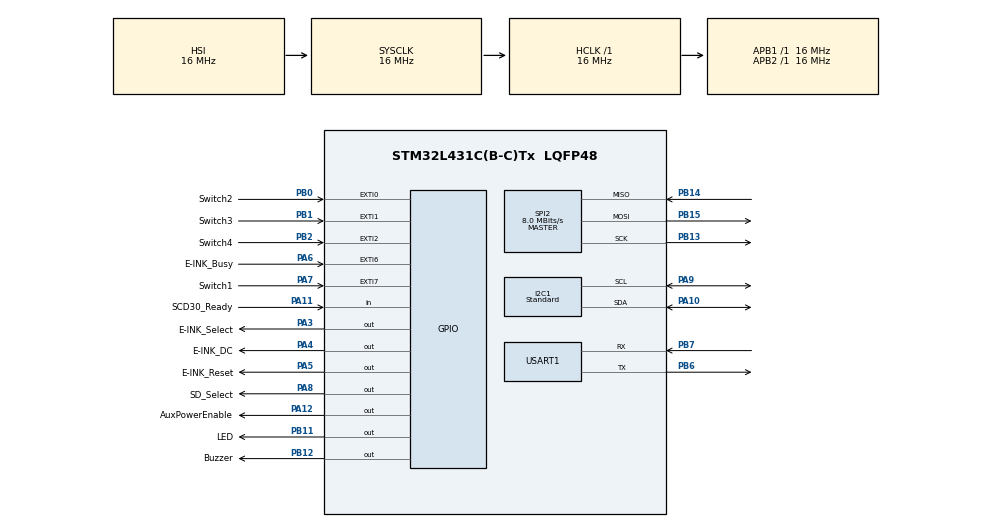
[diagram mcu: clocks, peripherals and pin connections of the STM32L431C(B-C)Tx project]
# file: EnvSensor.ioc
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ADC1.Channel-0\#ChannelRegularConversion=ADC_CHANNEL_VREFINT
ADC1.ClockPrescaler=ADC_CLOCK_ASYNC_DIV64
ADC1.NbrOfConversionFlag=1
ADC1.OffsetNumber-0\#ChannelRegularConversion=ADC_OFFSET_NONE
ADC1.Rank-0\#ChannelRegularConversion=1
ADC1.Resolution=ADC_RESOLUTION_10B
ADC1.SamplingTime-0\#ChannelRegularConversion=ADC_SAMPLETIME_2CYCLES_5
ADC1.master=1
CRC.DefaultInitValueUse=DEFAULT_INIT_VALUE_ENABLE
CRC.DefaultPolynomialUse=DEFAULT_POLYNOMIAL_ENABLE
FATFS._FS_LOCK=2
FATFS._MAX_SS=1024
FATFS._USE_LFN=1
I2C1.I2C_Speed_Mode=I2C_Standard
I2C1.NoStretchMode=I2C_NOSTRETCH_DISABLE
I2C1.Timing=0x00303D5B
Mcu.Family=STM32L4
Mcu.Name=STM32L431C(B-C)Tx
Mcu.Package=LQFP48
Mcu.UserConstants=READOUT_RETRY_INTERVAL,0.5;DISPLAY_REFRESH_INTERVAL,5 * 60;MEASUREMENT_INTERVAL,60
NVIC.EXTI0_IRQn=true\:0\:0\:false\:false\:true\:true\:true
NVIC.EXTI1_IRQn=true\:0\:0\:false\:false\:true\:true\:true
NVIC.EXTI2_IRQn=true\:0\:0\:false\:false\:true\:true\:true
NVIC.EXTI9_5_IRQn=true\:0\:0\:false\:false\:true\:true\:true
NVIC.PriorityGroup=NVIC_PRIORITYGROUP_4
NVIC.RTC_WKUP_IRQn=true\:0\:0\:false\:false\:true\:true\:true
NVIC.TIM1_BRK_TIM15_IRQn=true\:0\:0\:false\:false\:true\:true\:true
NVIC.TIM2_IRQn=true\:0\:0\:false\:false\:true\:true\:true
PA10.Mode=I2C
PA10.Signal=I2C1_SDA
PA11.GPIO_Label=SCD30_Ready
PA11.Signal=GPIO_Input
PA12.GPIO_Label=AuxPowerEnable
PA12.Signal=GPIO_Output
PA13\ (JTMS-SWDIO).Mode=Trace_Asynchronous_SW
PA13\ (JTMS-SWDIO).Signal=SYS_JTMS-SWDIO
PA14\ (JTCK-SWCLK).Mode=Trace_Asynchronous_SW
PA14\ (JTCK-SWCLK).Signal=SYS_JTCK-SWCLK
PA3.GPIO_Label=E-INK_Select
PA3.PinState=GPIO_PIN_SET
PA3.Signal=GPIO_Output
PA4.GPIO_Label=E-INK_DC
PA4.Signal=GPIO_Output
PA5.GPIO_Label=E-INK_Reset
PA5.PinState=GPIO_PIN_RESET
PA5.Signal=GPIO_Output
PA6.GPIO_Label=E-INK_Busy
PA6.Signal=GPXTI6
PA7.GPIO_Label=Switch1
PA7.GPIO_ModeDefaultEXTI=GPIO_MODE_IT_FALLING
PA7.Signal=GPXTI7
PA8.GPIO_Label=SD_Select
PA8.PinState=GPIO_PIN_SET
PA8.Signal=GPIO_Output
PA9.Mode=I2C
PA9.Signal=I2C1_SCL
PB0.GPIO_Label=Switch2
PB0.GPIO_ModeDefaultEXTI=GPIO_MODE_IT_FALLING
PB0.Signal=GPXTI0
PB1.GPIO_Label=Switch3
PB1.GPIO_ModeDefaultEXTI=GPIO_MODE_IT_FALLING
PB1.Signal=GPXTI1
PB11.GPIO_Label=LED
PB11.Signal=GPIO_Output
PB12.GPIO_Label=Buzzer
PB12.Signal=GPIO_Output
PB13.Mode=Full_Duplex_Master
PB13.Signal=SPI2_SCK
PB14.Mode=Full_Duplex_Master
PB14.Signal=SPI2_MISO
PB15.Mode=Full_Duplex_Master
PB15.Signal=SPI2_MOSI
PB2.GPIO_Label=Switch4
PB2.GPIO_ModeDefaultEXTI=GPIO_MODE_IT_FALLING
PB2.Signal=GPXTI2
PB3\ (JTDO-TRACESWO).Mode=Trace_Asynchronous_SW
PB3\ (JTDO-TRACESWO).Signal=SYS_JTDO-SWO
PB6.Mode=Asynchronous
PB6.Signal=USART1_TX
PB7.Mode=Asynchronous
PB7.Signal=USART1_RX
PC14-OSC32_IN\ (PC14).Mode=LSE-External-Oscillator
PC14-OSC32_IN\ (PC14).Signal=RCC_OSC32_IN
PC15-OSC32_OUT\ (PC15).Mode=LSE-External-Oscillator
PC15-OSC32_OUT\ (PC15).Signal=RCC_OSC32_OUT
ProjectManager.HeapSize=0x100
ProjectManager.StackSize=0x400
ProjectManager.TargetToolchain=STM32CubeIDE
RCC.ADCFreq_Value=32000000
RCC.AHBFreq_Value=16000000
RCC.APB1Freq_Value=16000000
RCC.APB1TimFreq_Value=16000000
RCC.APB2Freq_Value=16000000
RCC.APB2TimFreq_Value=16000000
RCC.CortexFreq_Value=16000000
RCC.HCLKFreq_Value=16000000
RCC.HSE_VALUE=8000000
RCC.HSI48_VALUE=48000000
RCC.HSI_VALUE=16000000
RCC.MSI_VALUE=4000000
RCC.PLLSAI1N=16
RCC.RTCClockSelection=RCC_RTCCLKSOURCE_LSE
RCC.SYSCLKFreq_VALUE=16000000
RCC.SYSCLKSource=RCC_SYSCLKSOURCE_HSI
RCC.VCOOutputFreq_Value=32000000
RTC.AsynchPrediv=127
RTC.Date=1
RTC.Format=RTC_FORMAT_BIN
RTC.Month=RTC_MONTH_JANUARY
RTC.WakeUpClock-WakeUp=RTC_WAKEUPCLOCK_CK_SPRE_16BITS
RTC.WakeUpCounter-WakeUp=DISPLAY_REFRESH_INTERVAL - 1
RTC.Year=21
SPI2.BaudRatePrescaler=SPI_BAUDRATEPRESCALER_2
SPI2.CalculateBaudRate=8.0 MBits/s
SPI2.DataSize=SPI_DATASIZE_8BIT
SPI2.Direction=SPI_DIRECTION_2LINES
SPI2.Mode=SPI_MODE_MASTER
SPI2.NSSPMode=SPI_NSS_PULSE_ENABLE
SPI2.VirtualType=VM_MASTER
STMicroelectronics.X-CUBE-TOUCHGFX.4.15.0.ApplicationCcGraphicsJjApplication=TouchGFXOoGenerator
STMicroelectronics.X-CUBE-TOUCHGFX.4.15.0.tgfx_buffering_strategy=Single
STMicroelectronics.X-CUBE-TOUCHGFX.4.15.0.tgfx_custom_height=300
STMicroelectronics.X-CUBE-TOUCHGFX.4.15.0.tgfx_custom_width=400
STMicroelectronics.X-CUBE-TOUCHGFX.4.15.0.tgfx_pixel_format=Grey2\:2
TIM15.Period=15624 * 4 * READOUT_RETRY_INTERVAL
TIM15.Prescaler=255
TIM2.ClockDivision=TIM_CLOCKDIVISION_DIV1
TIM2.Period=15625 * 4 * MEASUREMENT_INTERVAL - 1
TIM2.Prescaler=255
USART1.VirtualMode-Asynchronous=VM_ASYNC
VP_ADC1_Vref_Input.Mode=IN-Vrefint
VP_CRC_VS_CRC.Mode=CRC_Activate
VP_FATFS_VS_Generic.Mode=User_defined
VP_RTC_VS_RTC_Activate.Mode=RTC_Enabled
VP_RTC_VS_RTC_Calendar.Mode=RTC_Calendar
VP_RTC_VS_RTC_WakeUp_intern.Mode=WakeUp
VP_STMicroelectronics.X-CUBE-TOUCHGFX_VS_GraphicsJjApplication_4.15.0.Mode=GraphicsJjApplication
VP_TIM15_VS_ClockSourceINT.Mode=Internal
VP_TIM2_VS_ClockSourceINT.Mode=Internal
board=custom

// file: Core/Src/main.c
/* USER CODE BEGIN Header */
/**
  ******************************************************************************
  * @file           : main.c
  * @brief          : Main program body
  ******************************************************************************
  * @attention
  *
  * <h2><center>&copy; Copyright (c) 2020 STMicroelectronics.
  * All rights reserved.</center></h2>
  *
  * This software component is licensed by ST under BSD 3-Clause license,
  * the "License"; You may not use this file except in compliance with the
  * License. You may obtain a copy of the License at:
  *                        opensource.org/licenses/BSD-3-Clause
  *
  ******************************************************************************
  */
/* USER CODE END Header */
#include "main.h"
#include "fatfs.h"
#include "app_touchgfx.h"

/* USER CODE BEGIN Includes */

#include "EnvSensor.hpp"

/* USER CODE END Includes */

ADC_HandleTypeDef hadc1;

CRC_HandleTypeDef hcrc;

I2C_HandleTypeDef hi2c1;

RTC_HandleTypeDef hrtc;

SPI_HandleTypeDef hspi2;

TIM_HandleTypeDef htim2;
TIM_HandleTypeDef htim15;

UART_HandleTypeDef huart1;

void SystemClock_Config(void);
static void MX_GPIO_Init(void);
static void MX_I2C1_Init(void);
static void MX_SPI2_Init(void);
static void MX_USART1_UART_Init(void);
static void MX_CRC_Init(void);
static void MX_TIM2_Init(void);
static void MX_TIM15_Init(void);
static void MX_RTC_Init(void);
static void MX_ADC1_Init(void);

int main(void)
{

  /* MCU Configuration--------------------------------------------------------*/

  /* Reset of all peripherals, Initializes the Flash interface and the Systick. */
  HAL_Init();

  /* Configure the system clock */
  SystemClock_Config();

  /* Initialize all configured peripherals */
  MX_GPIO_Init();
  MX_I2C1_Init();
  MX_SPI2_Init();
  MX_USART1_UART_Init();
  MX_CRC_Init();
  MX_TIM2_Init();
  MX_TIM15_Init();
  MX_RTC_Init();
  MX_ADC1_Init();
  MX_FATFS_Init();
  MX_TouchGFX_Init();
  /* USER CODE BEGIN 2 */

  // prevent Tim15 from firing interrupt right after starting it
  __HAL_TIM_CLEAR_FLAG(&htim15, TIM_SR_UIF);

  EnvSensor_Init();

  // make initial draw
  MX_TouchGFX_Process();
uint32_t duration;
  /* USER CODE END 2 */

  /* Infinite loop */
  /* USER CODE BEGIN WHILE */
  while (1)
  {
	  EnvSensor_Loop();
	  uint32_t start = HAL_GetTick();
    /* USER CODE END WHILE */

  MX_TouchGFX_Process();
    /* USER CODE BEGIN 3 */
  	  duration = HAL_GetTick() - start;
  	  if (duration > 0) {
  		  duration++;
  	  }
  }
  /* USER CODE END 3 */
}

void SystemClock_Config(void)
{
  RCC_OscInitTypeDef RCC_OscInitStruct = {0};
  RCC_ClkInitTypeDef RCC_ClkInitStruct = {0};
  RCC_PeriphCLKInitTypeDef PeriphClkInit = {0};

  /** Configure LSE Drive Capability
  */
  HAL_PWR_EnableBkUpAccess();
  __HAL_RCC_LSEDRIVE_CONFIG(RCC_LSEDRIVE_LOW);
  /** Initializes the RCC Oscillators according to the specified parameters
  * in the RCC_OscInitTypeDef structure.
  */
  RCC_OscInitStruct.OscillatorType = RCC_OSCILLATORTYPE_HSI|RCC_OSCILLATORTYPE_LSE
                              |RCC_OSCILLATORTYPE_MSI;
  RCC_OscInitStruct.LSEState = RCC_LSE_ON;
  RCC_OscInitStruct.HSIState = RCC_HSI_ON;
  RCC_OscInitStruct.HSICalibrationValue = RCC_HSICALIBRATION_DEFAULT;
  RCC_OscInitStruct.MSIState = RCC_MSI_ON;
  RCC_OscInitStruct.MSICalibrationValue = 0;
  RCC_OscInitStruct.MSIClockRange = RCC_MSIRANGE_6;
  RCC_OscInitStruct.PLL.PLLState = RCC_PLL_NONE;
  if (HAL_RCC_OscConfig(&RCC_OscInitStruct) != HAL_OK)
  {
    Error_Handler();
  }
  /** Initializes the CPU, AHB and APB buses clocks
  */
  RCC_ClkInitStruct.ClockType = RCC_CLOCKTYPE_HCLK|RCC_CLOCKTYPE_SYSCLK
                              |RCC_CLOCKTYPE_PCLK1|RCC_CLOCKTYPE_PCLK2;
  RCC_ClkInitStruct.SYSCLKSource = RCC_SYSCLKSOURCE_HSI;
  RCC_ClkInitStruct.AHBCLKDivider = RCC_SYSCLK_DIV1;
  RCC_ClkInitStruct.APB1CLKDivider = RCC_HCLK_DIV1;
  RCC_ClkInitStruct.APB2CLKDivider = RCC_HCLK_DIV1;

  if (HAL_RCC_ClockConfig(&RCC_ClkInitStruct, FLASH_LATENCY_0) != HAL_OK)
  {
    Error_Handler();
  }
  PeriphClkInit.PeriphClockSelection = RCC_PERIPHCLK_RTC|RCC_PERIPHCLK_USART1
                              |RCC_PERIPHCLK_I2C1|RCC_PERIPHCLK_ADC;
  PeriphClkInit.Usart1ClockSelection = RCC_USART1CLKSOURCE_PCLK2;
  PeriphClkInit.I2c1ClockSelection = RCC_I2C1CLKSOURCE_PCLK1;
  PeriphClkInit.AdcClockSelection = RCC_ADCCLKSOURCE_PLLSAI1;
  PeriphClkInit.RTCClockSelection = RCC_RTCCLKSOURCE_LSE;
  PeriphClkInit.PLLSAI1.PLLSAI1Source = RCC_PLLSOURCE_MSI;
  PeriphClkInit.PLLSAI1.PLLSAI1M = 1;
  PeriphClkInit.PLLSAI1.PLLSAI1N = 16;
  PeriphClkInit.PLLSAI1.PLLSAI1P = RCC_PLLP_DIV7;
  PeriphClkInit.PLLSAI1.PLLSAI1Q = RCC_PLLQ_DIV2;
  PeriphClkInit.PLLSAI1.PLLSAI1R = RCC_PLLR_DIV2;
  PeriphClkInit.PLLSAI1.PLLSAI1ClockOut = RCC_PLLSAI1_ADC1CLK;
  if (HAL_RCCEx_PeriphCLKConfig(&PeriphClkInit) != HAL_OK)
  {
    Error_Handler();
  }
  /** Configure the main internal regulator output voltage
  */
  if (HAL_PWREx_ControlVoltageScaling(PWR_REGULATOR_VOLTAGE_SCALE1) != HAL_OK)
  {
    Error_Handler();
  }
  /** Enable MSI Auto calibration
  */
  HAL_RCCEx_EnableMSIPLLMode();
}

static void MX_ADC1_Init(void)
{

  ADC_ChannelConfTypeDef sConfig = {0};

  /** Common config
  */
  hadc1.Instance = ADC1;
  hadc1.Init.ClockPrescaler = ADC_CLOCK_ASYNC_DIV64;
  hadc1.Init.Resolution = ADC_RESOLUTION_10B;
  hadc1.Init.DataAlign = ADC_DATAALIGN_RIGHT;
  hadc1.Init.ScanConvMode = ADC_SCAN_DISABLE;
  hadc1.Init.EOCSelection = ADC_EOC_SINGLE_CONV;
  hadc1.Init.LowPowerAutoWait = DISABLE;
  hadc1.Init.ContinuousConvMode = DISABLE;
  hadc1.Init.NbrOfConversion = 1;
  hadc1.Init.DiscontinuousConvMode = DISABLE;
  hadc1.Init.ExternalTrigConv = ADC_SOFTWARE_START;
  hadc1.Init.ExternalTrigConvEdge = ADC_EXTERNALTRIGCONVEDGE_NONE;
  hadc1.Init.DMAContinuousRequests = DISABLE;
  hadc1.Init.Overrun = ADC_OVR_DATA_PRESERVED;
  hadc1.Init.OversamplingMode = DISABLE;
  if (HAL_ADC_Init(&hadc1) != HAL_OK)
  {
    Error_Handler();
  }
  /** Configure Regular Channel
  */
  sConfig.Channel = ADC_CHANNEL_VREFINT;
  sConfig.Rank = ADC_REGULAR_RANK_1;
  sConfig.SamplingTime = ADC_SAMPLETIME_2CYCLES_5;
  sConfig.SingleDiff = ADC_SINGLE_ENDED;
  sConfig.OffsetNumber = ADC_OFFSET_NONE;
  sConfig.Offset = 0;
  if (HAL_ADC_ConfigChannel(&hadc1, &sConfig) != HAL_OK)
  {
    Error_Handler();
  }

}

static void MX_CRC_Init(void)
{

  hcrc.Instance = CRC;
  hcrc.Init.DefaultPolynomialUse = DEFAULT_POLYNOMIAL_ENABLE;
  hcrc.Init.DefaultInitValueUse = DEFAULT_INIT_VALUE_ENABLE;
  hcrc.Init.InputDataInversionMode = CRC_INPUTDATA_INVERSION_NONE;
  hcrc.Init.OutputDataInversionMode = CRC_OUTPUTDATA_INVERSION_DISABLE;
  hcrc.InputDataFormat = CRC_INPUTDATA_FORMAT_BYTES;
  if (HAL_CRC_Init(&hcrc) != HAL_OK)
  {
    Error_Handler();
  }

}

static void MX_I2C1_Init(void)
{

  hi2c1.Instance = I2C1;
  hi2c1.Init.Timing = 0x00303D5B;
  hi2c1.Init.OwnAddress1 = 0;
  hi2c1.Init.AddressingMode = I2C_ADDRESSINGMODE_7BIT;
  hi2c1.Init.DualAddressMode = I2C_DUALADDRESS_DISABLE;
  hi2c1.Init.OwnAddress2 = 0;
  hi2c1.Init.OwnAddress2Masks = I2C_OA2_NOMASK;
  hi2c1.Init.GeneralCallMode = I2C_GENERALCALL_DISABLE;
  hi2c1.Init.NoStretchMode = I2C_NOSTRETCH_DISABLE;
  if (HAL_I2C_Init(&hi2c1) != HAL_OK)
  {
    Error_Handler();
  }
  /** Configure Analogue filter
  */
  if (HAL_I2CEx_ConfigAnalogFilter(&hi2c1, I2C_ANALOGFILTER_ENABLE) != HAL_OK)
  {
    Error_Handler();
  }
  /** Configure Digital filter
  */
  if (HAL_I2CEx_ConfigDigitalFilter(&hi2c1, 0) != HAL_OK)
  {
    Error_Handler();
  }

}

static void MX_RTC_Init(void)
{

  RTC_TimeTypeDef sTime = {0};
  RTC_DateTypeDef sDate = {0};

  /** Initialize RTC Only
  */
  hrtc.Instance = RTC;
  hrtc.Init.HourFormat = RTC_HOURFORMAT_24;
  hrtc.Init.AsynchPrediv = 127;
  hrtc.Init.SynchPrediv = 255;
  hrtc.Init.OutPut = RTC_OUTPUT_DISABLE;
  hrtc.Init.OutPutRemap = RTC_OUTPUT_REMAP_NONE;
  hrtc.Init.OutPutPolarity = RTC_OUTPUT_POLARITY_HIGH;
  hrtc.Init.OutPutType = RTC_OUTPUT_TYPE_OPENDRAIN;
  if (HAL_RTC_Init(&hrtc) != HAL_OK)
  {
    Error_Handler();
  }

  /** Initialize RTC and set the Time and Date
  */
  sTime.Hours = 0;
  sTime.Minutes = 0;
  sTime.Seconds = 0;
  sTime.DayLightSaving = RTC_DAYLIGHTSAVING_NONE;
  sTime.StoreOperation = RTC_STOREOPERATION_RESET;
  if (HAL_RTC_SetTime(&hrtc, &sTime, RTC_FORMAT_BIN) != HAL_OK)
  {
    Error_Handler();
  }
  sDate.WeekDay = RTC_WEEKDAY_MONDAY;
  sDate.Month = RTC_MONTH_JANUARY;
  sDate.Date = 1;
  sDate.Year = 21;

  if (HAL_RTC_SetDate(&hrtc, &sDate, RTC_FORMAT_BIN) != HAL_OK)
  {
    Error_Handler();
  }
  /** Enable the WakeUp
  */
  if (HAL_RTCEx_SetWakeUpTimer_IT(&hrtc, DISPLAY_REFRESH_INTERVAL - 1, RTC_WAKEUPCLOCK_CK_SPRE_16BITS) != HAL_OK)
  {
    Error_Handler();
  }

}

static void MX_SPI2_Init(void)
{

  /* SPI2 parameter configuration*/
  hspi2.Instance = SPI2;
  hspi2.Init.Mode = SPI_MODE_MASTER;
  hspi2.Init.Direction = SPI_DIRECTION_2LINES;
  hspi2.Init.DataSize = SPI_DATASIZE_8BIT;
  hspi2.Init.CLKPolarity = SPI_POLARITY_LOW;
  hspi2.Init.CLKPhase = SPI_PHASE_1EDGE;
  hspi2.Init.NSS = SPI_NSS_SOFT;
  hspi2.Init.BaudRatePrescaler = SPI_BAUDRATEPRESCALER_2;
  hspi2.Init.FirstBit = SPI_FIRSTBIT_MSB;
  hspi2.Init.TIMode = SPI_TIMODE_DISABLE;
  hspi2.Init.CRCCalculation = SPI_CRCCALCULATION_DISABLE;
  hspi2.Init.CRCPolynomial = 7;
  hspi2.Init.CRCLength = SPI_CRC_LENGTH_DATASIZE;
  hspi2.Init.NSSPMode = SPI_NSS_PULSE_ENABLE;
  if (HAL_SPI_Init(&hspi2) != HAL_OK)
  {
    Error_Handler();
  }

}

static void MX_TIM2_Init(void)
{

  TIM_ClockConfigTypeDef sClockSourceConfig = {0};
  TIM_MasterConfigTypeDef sMasterConfig = {0};

  htim2.Instance = TIM2;
  htim2.Init.Prescaler = 255;
  htim2.Init.CounterMode = TIM_COUNTERMODE_UP;
  htim2.Init.Period = 15625 * 4 * MEASUREMENT_INTERVAL - 1;
  htim2.Init.ClockDivision = TIM_CLOCKDIVISION_DIV1;
  htim2.Init.AutoReloadPreload = TIM_AUTORELOAD_PRELOAD_DISABLE;
  if (HAL_TIM_Base_Init(&htim2) != HAL_OK)
  {
    Error_Handler();
  }
  sClockSourceConfig.ClockSource = TIM_CLOCKSOURCE_INTERNAL;
  if (HAL_TIM_ConfigClockSource(&htim2, &sClockSourceConfig) != HAL_OK)
  {
    Error_Handler();
  }
  sMasterConfig.MasterOutputTrigger = TIM_TRGO_RESET;
  sMasterConfig.MasterSlaveMode = TIM_MASTERSLAVEMODE_DISABLE;
  if (HAL_TIMEx_MasterConfigSynchronization(&htim2, &sMasterConfig) != HAL_OK)
  {
    Error_Handler();
  }

}

static void MX_TIM15_Init(void)
{

  TIM_ClockConfigTypeDef sClockSourceConfig = {0};
  TIM_MasterConfigTypeDef sMasterConfig = {0};

  htim15.Instance = TIM15;
  htim15.Init.Prescaler = 255;
  htim15.Init.CounterMode = TIM_COUNTERMODE_UP;
  htim15.Init.Period = 15624 * 4 * READOUT_RETRY_INTERVAL;
  htim15.Init.ClockDivision = TIM_CLOCKDIVISION_DIV1;
  htim15.Init.RepetitionCounter = 0;
  htim15.Init.AutoReloadPreload = TIM_AUTORELOAD_PRELOAD_DISABLE;
  if (HAL_TIM_Base_Init(&htim15) != HAL_OK)
  {
    Error_Handler();
  }
  sClockSourceConfig.ClockSource = TIM_CLOCKSOURCE_INTERNAL;
  if (HAL_TIM_ConfigClockSource(&htim15, &sClockSourceConfig) != HAL_OK)
  {
    Error_Handler();
  }
  sMasterConfig.MasterOutputTrigger = TIM_TRGO_RESET;
  sMasterConfig.MasterSlaveMode = TIM_MASTERSLAVEMODE_DISABLE;
  if (HAL_TIMEx_MasterConfigSynchronization(&htim15, &sMasterConfig) != HAL_OK)
  {
    Error_Handler();
  }

}

static void MX_USART1_UART_Init(void)
{

  huart1.Instance = USART1;
  huart1.Init.BaudRate = 115200;
  huart1.Init.WordLength = UART_WORDLENGTH_8B;
  huart1.Init.StopBits = UART_STOPBITS_1;
  huart1.Init.Parity = UART_PARITY_NONE;
  huart1.Init.Mode = UART_MODE_TX_RX;
  huart1.Init.HwFlowCtl = UART_HWCONTROL_NONE;
  huart1.Init.OverSampling = UART_OVERSAMPLING_16;
  huart1.Init.OneBitSampling = UART_ONE_BIT_SAMPLE_DISABLE;
  huart1.AdvancedInit.AdvFeatureInit = UART_ADVFEATURE_NO_INIT;
  if (HAL_UART_Init(&huart1) != HAL_OK)
  {
    Error_Handler();
  }

}

static void MX_GPIO_Init(void)
{
  GPIO_InitTypeDef GPIO_InitStruct = {0};

  /* GPIO Ports Clock Enable */
  __HAL_RCC_GPIOC_CLK_ENABLE();
  __HAL_RCC_GPIOA_CLK_ENABLE();
  __HAL_RCC_GPIOB_CLK_ENABLE();

  /*Configure GPIO pin Output Level */
  HAL_GPIO_WritePin(GPIOA, E_INK_Select_Pin|SD_Select_Pin, GPIO_PIN_SET);

  /*Configure GPIO pin Output Level */
  HAL_GPIO_WritePin(GPIOA, E_INK_DC_Pin|E_INK_Reset_Pin|AuxPowerEnable_Pin, GPIO_PIN_RESET);

  /*Configure GPIO pin Output Level */
  HAL_GPIO_WritePin(GPIOB, LED_Pin|Buzzer_Pin, GPIO_PIN_RESET);

  /*Configure GPIO pins : E_INK_Select_Pin E_INK_DC_Pin E_INK_Reset_Pin SD_Select_Pin
                           AuxPowerEnable_Pin */
  GPIO_InitStruct.Pin = E_INK_Select_Pin|E_INK_DC_Pin|E_INK_Reset_Pin|SD_Select_Pin
                          |AuxPowerEnable_Pin;
  GPIO_InitStruct.Mode = GPIO_MODE_OUTPUT_PP;
  GPIO_InitStruct.Pull = GPIO_NOPULL;
  GPIO_InitStruct.Speed = GPIO_SPEED_FREQ_LOW;
  HAL_GPIO_Init(GPIOA, &GPIO_InitStruct);

  /*Configure GPIO pin : E_INK_Busy_Pin */
  GPIO_InitStruct.Pin = E_INK_Busy_Pin;
  GPIO_InitStruct.Mode = GPIO_MODE_IT_RISING;
  GPIO_InitStruct.Pull = GPIO_NOPULL;
  HAL_GPIO_Init(E_INK_Busy_GPIO_Port, &GPIO_InitStruct);

  /*Configure GPIO pin : Switch1_Pin */
  GPIO_InitStruct.Pin = Switch1_Pin;
  GPIO_InitStruct.Mode = GPIO_MODE_IT_FALLING;
  GPIO_InitStruct.Pull = GPIO_NOPULL;
  HAL_GPIO_Init(Switch1_GPIO_Port, &GPIO_InitStruct);

  /*Configure GPIO pins : Switch2_Pin Switch3_Pin Switch4_Pin */
  GPIO_InitStruct.Pin = Switch2_Pin|Switch3_Pin|Switch4_Pin;
  GPIO_InitStruct.Mode = GPIO_MODE_IT_FALLING;
  GPIO_InitStruct.Pull = GPIO_NOPULL;
  HAL_GPIO_Init(GPIOB, &GPIO_InitStruct);

  /*Configure GPIO pins : LED_Pin Buzzer_Pin */
  GPIO_InitStruct.Pin = LED_Pin|Buzzer_Pin;
  GPIO_InitStruct.Mode = GPIO_MODE_OUTPUT_PP;
  GPIO_InitStruct.Pull = GPIO_NOPULL;
  GPIO_InitStruct.Speed = GPIO_SPEED_FREQ_LOW;
  HAL_GPIO_Init(GPIOB, &GPIO_InitStruct);

  /*Configure GPIO pin : SCD30_Ready_Pin */
  GPIO_InitStruct.Pin = SCD30_Ready_Pin;
  GPIO_InitStruct.Mode = GPIO_MODE_INPUT;
  GPIO_InitStruct.Pull = GPIO_NOPULL;
  HAL_GPIO_Init(SCD30_Ready_GPIO_Port, &GPIO_InitStruct);

  /* EXTI interrupt init*/
  HAL_NVIC_SetPriority(EXTI0_IRQn, 0, 0);
  HAL_NVIC_EnableIRQ(EXTI0_IRQn);

  HAL_NVIC_SetPriority(EXTI1_IRQn, 0, 0);
  HAL_NVIC_EnableIRQ(EXTI1_IRQn);

  HAL_NVIC_SetPriority(EXTI2_IRQn, 0, 0);
  HAL_NVIC_EnableIRQ(EXTI2_IRQn);

  HAL_NVIC_SetPriority(EXTI9_5_IRQn, 0, 0);
  HAL_NVIC_EnableIRQ(EXTI9_5_IRQn);

}

void Error_Handler(void)
{
  /* USER CODE BEGIN Error_Handler_Debug */
  /* User can add his own implementation to report the HAL error return state */

	LED_ON;

  /* USER CODE END Error_Handler_Debug */
}

/************************ (C) COPYRIGHT STMicroelectronics *****END OF FILE****/
